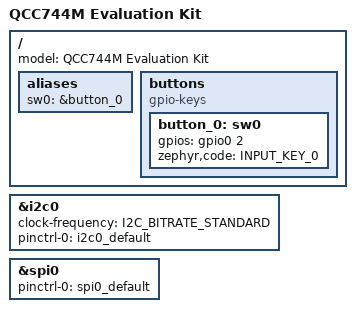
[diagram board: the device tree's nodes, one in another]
/*
 * Copyright (c) 2025-2026 MASSDRIVER EI (massdriver.space)
 *
 * SPDX-License-Identifier: Apache-2.0
 */

/dts-v1/;

#include "qcc744m.dtsi"
#include "qcc744m_evk-pinctrl.dtsi"

/ {
	model = "QCC744M Evaluation Kit";

	aliases {
		sw0 = &button_0;
	};

	buttons {
		compatible = "gpio-keys";

		button_0: sw0 {
			/* To use, CH347 DTR1 jumper must be removed */
			gpios = <&gpio0 2 (GPIO_ACTIVE_HIGH | GPIO_PULL_DOWN)>;
			zephyr,code = <INPUT_KEY_0>;
		};
	};
};

&i2c0 {
	status = "okay";
	clock-frequency = <I2C_BITRATE_STANDARD>;

	pinctrl-0 = <&i2c0_default>;
	pinctrl-names = "default";
};

&spi0 {
	status = "okay";

	pinctrl-0 = <&spi0_default>;
	pinctrl-names = "default";
};
